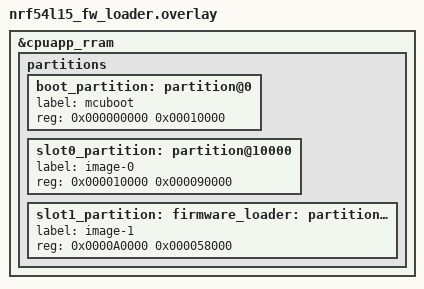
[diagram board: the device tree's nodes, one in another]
/*
 * Copyright (c) 2025 Nordic Semiconductor ASA
 *
 * SPDX-License-Identifier: Apache-2.0
 */

/delete-node/ &boot_partition;
/delete-node/ &slot0_partition;
/delete-node/ &slot1_partition;
/delete-node/ &slot0_ns_partition;
/delete-node/ &slot1_ns_partition;

&cpuapp_rram {
	partitions {
		boot_partition: partition@0 {
			label = "mcuboot";
			reg = <0x000000000 0x00010000>;
		};
		slot0_partition: partition@10000 {
			label = "image-0";
			reg = <0x000010000 0x000090000>;
		};
		slot1_partition: firmware_loader: partition@A0000 {
			label = "image-1";
			reg = <0x0000A0000 0x000058000>;
		};
	};
};
